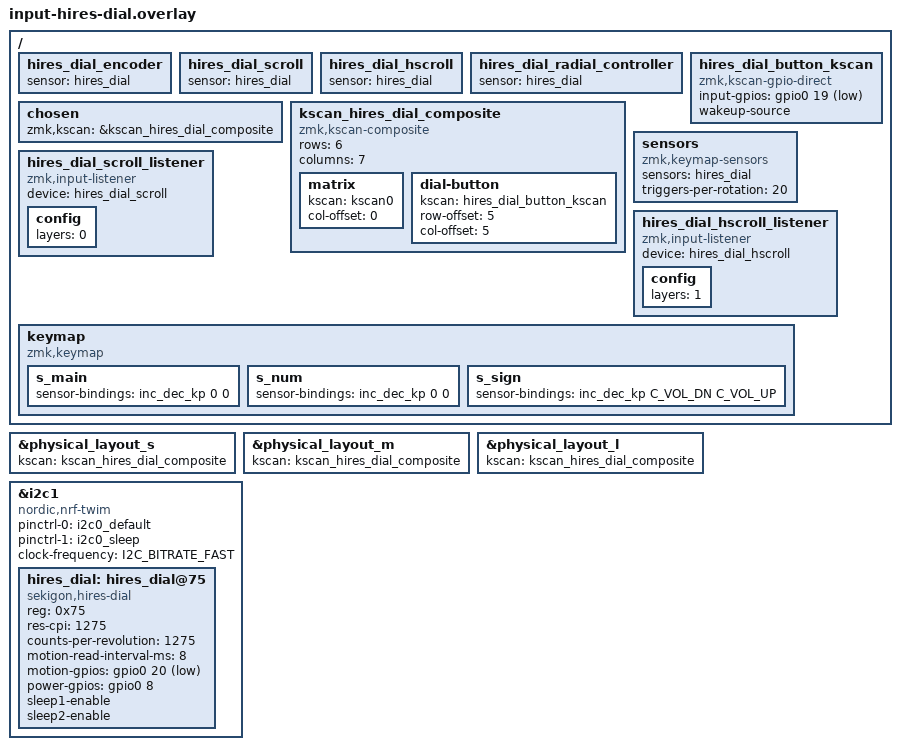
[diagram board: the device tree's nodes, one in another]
#include <zephyr/dt-bindings/gpio/gpio.h>
#include <zephyr/dt-bindings/i2c/i2c.h>
#include <zephyr/dt-bindings/input/input-event-codes.h>
#include <zephyr/dt-bindings/gpio/nordic-nrf-gpio.h>
#include <dt-bindings/zmk/keys.h>
#include <behaviors.dtsi>

/ {
    /* ★復活: 後付け設定のエラーを回避するためのベースノード */
    hires_dial_encoder: hires_dial_encoder {};
    hires_dial_scroll: hires_dial_scroll {};
    hires_dial_hscroll: hires_dial_hscroll {};
    hires_dial_radial_controller: hires_dial_radial_controller {};

    chosen {
        zmk,kscan = &kscan_hires_dial_composite;
    };

    hires_dial_button_kscan: hires_dial_button_kscan {
        compatible = "zmk,kscan-gpio-direct";
        input-gpios = <&gpio0 19 (GPIO_ACTIVE_LOW | GPIO_PULL_UP)>;
        wakeup-source;
    };

    kscan_hires_dial_composite: kscan_hires_dial_composite {
        compatible = "zmk,kscan-composite";
        rows = <6>;
        columns = <7>;

        matrix {
            kscan = <&kscan0>;
            col-offset = <0>;
        };

        dial-button {
            kscan = <&hires_dial_button_kscan>;
            row-offset = <5>;
            col-offset = <5>;
        };
    };

    sensors {
        compatible = "zmk,keymap-sensors";
        sensors = <&hires_dial>;
        triggers-per-rotation = <20>;
    };

    /* レイヤー0でのみ縦スクロールを有効にする */
    hires_dial_scroll_listener {
        compatible = "zmk,input-listener";
        device = <&hires_dial_scroll>;
        
        config {
            layers = <0>;
        };
    };

    /* レイヤー1でのみ横スクロールを有効にする */
    hires_dial_hscroll_listener {
        compatible = "zmk,input-listener";
        device = <&hires_dial_hscroll>;
        
        config {
            layers = <1>;
        };
    };
};

&physical_layout_s {
    kscan = <&kscan_hires_dial_composite>;
};

&physical_layout_m {
    kscan = <&kscan_hires_dial_composite>;
};

&physical_layout_l {
    kscan = <&kscan_hires_dial_composite>;
};

&i2c1 {
    status = "okay";
    compatible = "nordic,nrf-twim";
    pinctrl-0 = <&i2c0_default>;
    pinctrl-1 = <&i2c0_sleep>;
    pinctrl-names = "default", "sleep";
    clock-frequency = <I2C_BITRATE_FAST>;

    hires_dial: hires_dial@75 {
        status = "okay";
        compatible = "sekigon,hires-dial";
        reg = <0x75>;
        res-cpi = <1275>;
        counts-per-revolution = <1275>;
        motion-read-interval-ms = <8>;
        motion-gpios = <&gpio0 20 (GPIO_ACTIVE_LOW | GPIO_PULL_UP)>;
        power-gpios = <&gpio0 8 (GPIO_ACTIVE_HIGH | NRF_GPIO_DRIVE_H0H1)>;
        sleep1-enable;
        sleep2-enable;
    };
};

&hires_dial_encoder {
    sensor = <&hires_dial>;
};

&hires_dial_scroll {
    sensor = <&hires_dial>;
};

&hires_dial_hscroll {
    sensor = <&hires_dial>;
};

&hires_dial_radial_controller {
    sensor = <&hires_dial>;
};

/* ======================================================================== */
/* 修正版: Overlayファイルからキーマップに sensor-bindings を安全に注入する */
/* ======================================================================== */

/ {
    /* 
     * .keymap ファイルよりも先にパースされるため、
     * ここでノードの「枠組み（ラベル）」だけを事前宣言しておきます。
     */
    keymap {
        compatible = "zmk,keymap";
        
        s_main: s_main {};
        s_num: s_num {};
        s_sign: s_sign {};
    };
};

/* 
 * 上記で宣言したラベルに対して、sensor-bindings を追加します。
 * 後から読み込まれる .keymap ファイルの設定と自動的にマージされます。
 */
&s_main {
    sensor-bindings = <&inc_dec_kp 0 0>;
};

&s_num {
    sensor-bindings = <&inc_dec_kp 0 0>;
};

&s_sign {
    sensor-bindings = <&inc_dec_kp C_VOL_DN C_VOL_UP>;
};
